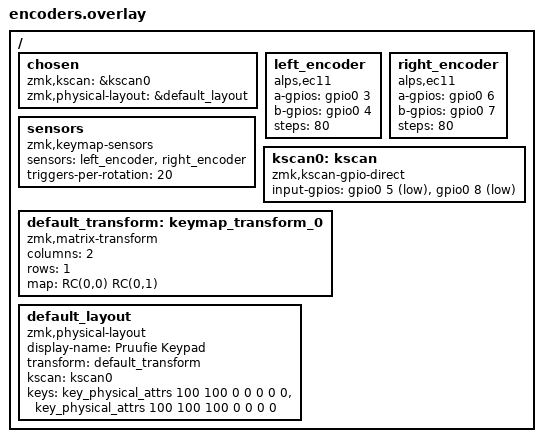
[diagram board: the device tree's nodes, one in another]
#include <physical_layouts.dtsi>
#include <dt-bindings/zmk/matrix_transform.h>

/ {
    chosen {
        zmk,kscan = &kscan0;
        zmk,physical-layout = &default_layout;
    };

    left_encoder: left_encoder {
        compatible = "alps,ec11";
        a-gpios = <&gpio0 3 (GPIO_ACTIVE_HIGH | GPIO_PULL_UP)>;
        b-gpios = <&gpio0 4 (GPIO_ACTIVE_HIGH | GPIO_PULL_UP)>;
        steps = <80>;
        status = "okay";
    };

    right_encoder: right_encoder {
        compatible = "alps,ec11";
        a-gpios = <&gpio0 6 (GPIO_ACTIVE_HIGH | GPIO_PULL_UP)>;
        b-gpios = <&gpio0 7 (GPIO_ACTIVE_HIGH | GPIO_PULL_UP)>;
        steps = <80>;
        status = "okay";
    };

    sensors: sensors {
        compatible = "zmk,keymap-sensors";
        sensors = <&left_encoder &right_encoder>;
        triggers-per-rotation = <20>;
    };

    kscan0: kscan {
        compatible = "zmk,kscan-gpio-direct";
        input-gpios = <&gpio0 5 (GPIO_ACTIVE_LOW | GPIO_PULL_UP)>,
                      <&gpio0 8 (GPIO_ACTIVE_LOW | GPIO_PULL_UP)>;
    };

    default_transform: keymap_transform_0 {
        compatible = "zmk,matrix-transform";
        columns = <2>;
        rows = <1>;
        map = <
            RC(0,0) RC(0,1)
        >;
    };

    default_layout: default_layout {
        compatible = "zmk,physical-layout";
        display-name = "Pruufie Keypad";
        transform = <&default_transform>;
        kscan = <&kscan0>;

        keys  //                     w   h    x    y   rot  rx   ry
            // Row 0
            = <&key_physical_attrs 100 100    0    0    0    0    0>
            , <&key_physical_attrs 100 100  100    0    0    0    0>
            ;
    };
};
